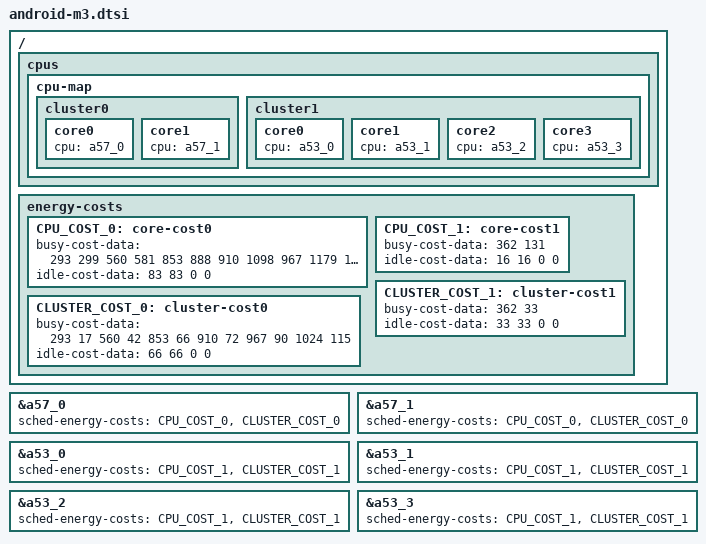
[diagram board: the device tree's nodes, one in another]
/*
 * Device Tree Source for the Android
 *
 * Copyright (C) 2018 GlobalLogic
 *
 * This file is licensed under the terms of the GNU General Public License
 * version 2.  This program is licensed "as is" without any warranty of any
 * kind, whether express or implied.
 */

#include "android-fstab.dtsi"
#include "android-common.dtsi"

/ {
	cpus {
		cpu-map {
			cluster0 {
				core0 {
					cpu = <&a57_0>;
				};
				core1 {
					cpu = <&a57_1>;
				};
			};

			cluster1 {
				core0 {
					cpu = <&a53_0>;
				};
				core1 {
					cpu = <&a53_1>;
				};
				core2 {
					cpu = <&a53_2>;
				};
				core3 {
					cpu = <&a53_3>;
				};
			};
		};
	};

	energy-costs {
		CPU_COST_0: core-cost0 {
			busy-cost-data = <
				293   299
				560   581
				853   888
				910   1098
				967   1179
				1024  1421
			>;
			idle-cost-data = <
				83
				83
				0
				0
			>;
		};
		CPU_COST_1: core-cost1 {
			busy-cost-data = <
				362   131
			>;
			idle-cost-data = <
				16
				16
				0
				0
			>;
		};
		CLUSTER_COST_0: cluster-cost0 {
			busy-cost-data = <
				293   17
				560   42
				853   66
				910   72
				967   90
				1024  115
			>;
			idle-cost-data = <
				66
				66
				0
				0
			>;
		};
		CLUSTER_COST_1: cluster-cost1 {
			busy-cost-data = <
				362   33
			>;
			idle-cost-data = <
				33
				33
				0
				0
			>;
		};
	};
};

&a57_0 {
	sched-energy-costs = <&CPU_COST_0 &CLUSTER_COST_0>;
};

&a57_1 {
	sched-energy-costs = <&CPU_COST_0 &CLUSTER_COST_0>;
};

&a53_0 {
	sched-energy-costs = <&CPU_COST_1 &CLUSTER_COST_1>;
};

&a53_1 {
	sched-energy-costs = <&CPU_COST_1 &CLUSTER_COST_1>;
};

&a53_2 {
	sched-energy-costs = <&CPU_COST_1 &CLUSTER_COST_1>;
};

&a53_3 {
	sched-energy-costs = <&CPU_COST_1 &CLUSTER_COST_1>;
};
